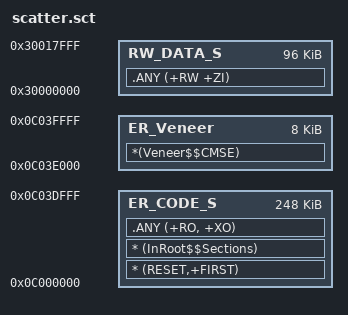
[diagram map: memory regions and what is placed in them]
LR_CODE_S 0xC000000 0x3E000 {
  ER_CODE_S 0xC000000 0x3E000 {
  	* (RESET,+FIRST)
    * (InRoot$$Sections)
    .ANY (+RO, +XO)
  }
  RW_DATA_S 0x30000000 0x18000 {
    .ANY (+RW +ZI)
  }
}
LR_Veneer 0xC03E000 0x2000 {
  ER_Veneer 0xC03E000 0x2000 {
  	*(Veneer$$CMSE)
  }
}
